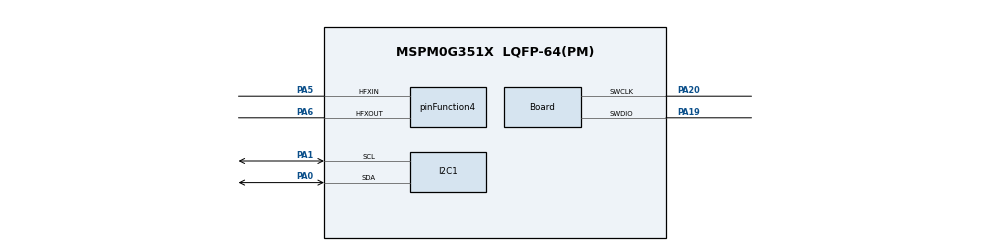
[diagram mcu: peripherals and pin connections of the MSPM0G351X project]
/**
 * @cliArgs --device "MSPM0G351X" --part "Default" --package "LQFP-64(PM)" --product "mspm0_sdk@2.05.01.01"
 * @versions {"tool":"1.24.0+4110"}
 */

const GPIO   = scripting.addModule("/ti/driverlib/GPIO", {}, false);
const GPIO1  = GPIO.addInstance();
const SYSCTL = scripting.addModule("/ti/driverlib/SYSCTL");

/* ---- 80 MHz clock tree ---- */
SYSCTL.forceDefaultClkConfig = true;
SYSCTL.clockTreeEn           = true;
scripting.suppress("For best practices when the CPUCLK is running at 32MHz and above, clear the flash status bit using DL_FlashCTL_executeClearStatus\\(\\) before executing any flash operation\\. Otherwise there may be false positives\\.", SYSCTL);

const divider9       = system.clockTree["UDIV"];
divider9.divideValue = 2;
const multiplier2         = system.clockTree["PLL_QDIV"];
multiplier2.multiplyValue = 4;
const mux4       = system.clockTree["EXHFMUX"];
mux4.inputSelect = "EXHFMUX_XTAL";
const mux8       = system.clockTree["HSCLKMUX"];
mux8.inputSelect = "HSCLKMUX_SYSPLL0";
const mux12       = system.clockTree["SYSPLLMUX"];
mux12.inputSelect = "zSYSPLLMUX_HFCLK";
const pinFunction4 = system.clockTree["HFXT"];
pinFunction4.inputFreq = 40;
pinFunction4.enable = true;
pinFunction4.HFXTStartup = 10;
pinFunction4.HFCLKMonitor = true;
pinFunction4.peripheral.$assign = "SYSCTL";
pinFunction4.peripheral.hfxInPin.$assign = "PA5";
pinFunction4.peripheral.hfxOutPin.$assign = "PA6";

/* ---- Board: SWD debug ---- */
const Board = scripting.addModule("/ti/driverlib/Board", {}, false);
Board.peripheral.$assign = "DEBUGSS";
Board.peripheral.swclkPin.$assign = "PA20";
Board.peripheral.swdioPin.$assign = "PA19";

/* ---- I2C0: PA0=SDA, PA1=SCL (hardware I2C, OLED + IMU shared bus) ---- */
const I2C  = scripting.addModule("/ti/driverlib/I2C", {}, false);
const I2C1 = I2C.addInstance();
I2C1.$name = "I2C_0";
I2C1.peripheral.$assign = "I2C0";
I2C1.peripheral.sdaPin.$assign = "PA0";
I2C1.peripheral.sclPin.$assign = "PA1";

/* GPIO definitions for IOMUX macros (used by OLED_driver.c) */
GPIO1.$name = "OLED";
GPIO1.associatedPins.create(2);
GPIO1.associatedPins[0].$name = "SDA";
GPIO1.associatedPins[0].assignedPort = "PORTA";
GPIO1.associatedPins[0].assignedPin = "0";
GPIO1.associatedPins[1].$name = "SCL";
GPIO1.associatedPins[1].assignedPort = "PORTA";
GPIO1.associatedPins[1].assignedPin = "1";

const ProjectConfig = scripting.addModule("/ti/project_config/ProjectConfig", {}, false);
ProjectConfig.migrationCondition = true;
